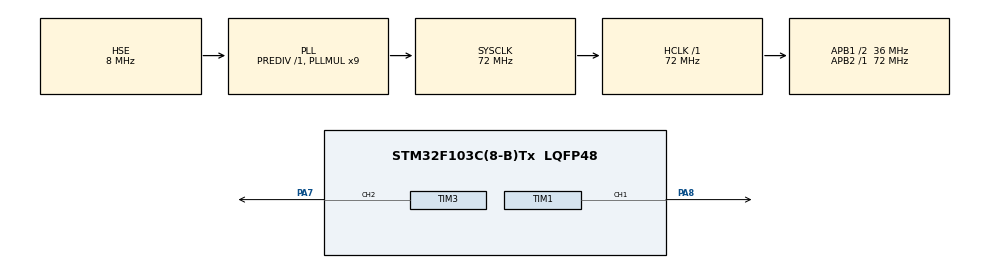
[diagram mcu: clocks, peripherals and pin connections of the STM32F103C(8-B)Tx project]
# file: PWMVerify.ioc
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Mcu.Family=STM32F1
Mcu.Name=STM32F103C(8-B)Tx
Mcu.Package=LQFP48
NVIC.PriorityGroup=NVIC_PRIORITYGROUP_4
PA13.Mode=Serial_Wire
PA13.Signal=SYS_JTMS-SWDIO
PA14.Mode=Serial_Wire
PA14.Signal=SYS_JTCK-SWCLK
PA7.Signal=S_TIM3_CH2
PA8.Signal=S_TIM1_CH1
PD0-OSC_IN.Mode=HSE-External-Oscillator
PD0-OSC_IN.Signal=RCC_OSC_IN
PD1-OSC_OUT.Mode=HSE-External-Oscillator
PD1-OSC_OUT.Signal=RCC_OSC_OUT
ProjectManager.HeapSize=0x200
ProjectManager.StackSize=0x400
ProjectManager.TargetToolchain=MDK-ARM V5.32
RCC.AHBFreq_Value=72000000
RCC.APB1CLKDivider=RCC_HCLK_DIV2
RCC.APB1Freq_Value=36000000
RCC.APB1TimFreq_Value=72000000
RCC.APB2Freq_Value=72000000
RCC.APB2TimFreq_Value=72000000
RCC.HCLKFreq_Value=72000000
RCC.PLLMUL=RCC_PLL_MUL9
RCC.PLLSourceVirtual=RCC_PLLSOURCE_HSE
RCC.SYSCLKFreq_VALUE=72000000
RCC.SYSCLKSource=RCC_SYSCLKSOURCE_PLLCLK
RCC.USBFreq_Value=72000000
SH.S_TIM1_CH1.0=TIM1_CH1,PWM Generation1 CH1
SH.S_TIM3_CH2.0=TIM3_CH2,PWM Generation2 CH2
TIM1.Channel-PWM\ Generation1\ CH1=TIM_CHANNEL_1
TIM3.Channel-PWM\ Generation2\ CH2=TIM_CHANNEL_2
VP_TIM1_VS_ClockSourceINT.Mode=Internal
VP_TIM3_VS_ClockSourceINT.Mode=Internal
board=custom

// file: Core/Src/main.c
/* USER CODE BEGIN Header */
/**
  ******************************************************************************
  * @file           : main.c
  * @brief          : Main program body
  ******************************************************************************
  * @attention
  *
  * Copyright (c) 2026 STMicroelectronics.
  * All rights reserved.
  *
  * This software is licensed under terms that can be found in the LICENSE file
  * in the root directory of this software component.
  * If no LICENSE file comes with this software, it is provided AS-IS.
  *
  ******************************************************************************
  */
/* USER CODE END Header */
#include "main.h"
#include "tim.h"
#include "gpio.h"

void SystemClock_Config(void);

int main(void)
{

  /* MCU Configuration--------------------------------------------------------*/

  /* Reset of all peripherals, Initializes the Flash interface and the Systick. */
  HAL_Init();

  /* Configure the system clock */
  SystemClock_Config();

  /* Initialize all configured peripherals */
  MX_GPIO_Init();
  MX_TIM1_Init();
  MX_TIM3_Init();
  /* USER CODE BEGIN 2 */
  /* ==========================================================================
   * 双定时器同频 PWM + 硬件主从触发死区（相移）
   *
   *   TIM1 (主) : PWM CH1 -> PA8   TRGO = Update Event
   *   TIM3 (从) : PWM CH2 -> PA7   Slave = Trigger Mode, TRGI = ITR0 (= TIM1 TRGO)
   *
   * 与 F4 参考工程 PWMGenerate 的实现保持一致:
   *   主从配置、CNT 预置、启动顺序全部集中在 MX_PWM_Start_PhaseLocked() 中,
   *   且放在 USER CODE 区, CubeMX 重新生成代码不会丢失。
   * ========================================================================== */

  /* 1) 设定两路 PWM 的占空比 */
  __HAL_TIM_SET_COMPARE(&htim1, TIM_CHANNEL_1, PWM_PULSE);    /* PA8: 高 [0, 1800)  */
  __HAL_TIM_SET_COMPARE(&htim3, TIM_CHANNEL_2, PWM_PULSE_T3); /* PA7: 高 [5, 1795)  */

  /* 2) 启动两路 PWM, 并一次性锁定 TIM1 / TIM3 的相位(死区) */
  MX_PWM_Start_PhaseLocked();

  /* USER CODE END 2 */

  /* Infinite loop */
  while (1)
  {

    /* USER CODE BEGIN 3 */
    /* ---- 调试用: 持续锁存寄存器, 在 Keil 的 Watch 窗口观察 -------------
     * g_dbg_tim3_cnt  : 若在不停变化 -> TIM3 计数器已被 TRGO 启动(正常)
     *                    若恒等于 3595   -> 没收到触发, 卡在预置值
     * g_dbg_tim3_sr   : bit6(TIF)=1 表示收到过 TRIGGER 事件
     * g_dbg_tim3_cr1  : bit0(CEN)=0 是触发模式的正常现象(由硬件 CNT_EN 启动)
     * g_dbg_tim1_cr2  : bit6:4(MMS) 应为 010 = TRGO 选更新事件
     * g_dbg_tim3_smcr : 应为 0x0006 (SMS=110 触发模式, TS=000 ITR0)
     * ------------------------------------------------------------------ */
    g_dbg_tim1_cr1  = TIM1->CR1;
    g_dbg_tim1_cr2  = TIM1->CR2;
    g_dbg_tim1_cnt  = TIM1->CNT;
    g_dbg_tim3_cr1  = TIM3->CR1;
    g_dbg_tim3_smcr = TIM3->SMCR;
    g_dbg_tim3_cnt  = TIM3->CNT;
    g_dbg_tim3_sr   = TIM3->SR;
  }
  /* USER CODE END 3 */
}

void SystemClock_Config(void)
{
  RCC_OscInitTypeDef RCC_OscInitStruct = {0};
  RCC_ClkInitTypeDef RCC_ClkInitStruct = {0};

  /** Initializes the RCC Oscillators according to the specified parameters
  * in the RCC_OscInitTypeDef structure.
  */
  RCC_OscInitStruct.OscillatorType = RCC_OSCILLATORTYPE_HSE;
  RCC_OscInitStruct.HSEState = RCC_HSE_ON;
  RCC_OscInitStruct.HSEPredivValue = RCC_HSE_PREDIV_DIV1;
  RCC_OscInitStruct.HSIState = RCC_HSI_ON;
  RCC_OscInitStruct.PLL.PLLState = RCC_PLL_ON;
  RCC_OscInitStruct.PLL.PLLSource = RCC_PLLSOURCE_HSE;
  RCC_OscInitStruct.PLL.PLLMUL = RCC_PLL_MUL9;
  if (HAL_RCC_OscConfig(&RCC_OscInitStruct) != HAL_OK)
  {
    Error_Handler();
  }

  /** Initializes the CPU, AHB and APB buses clocks
  */
  RCC_ClkInitStruct.ClockType = RCC_CLOCKTYPE_HCLK|RCC_CLOCKTYPE_SYSCLK
                              |RCC_CLOCKTYPE_PCLK1|RCC_CLOCKTYPE_PCLK2;
  RCC_ClkInitStruct.SYSCLKSource = RCC_SYSCLKSOURCE_PLLCLK;
  RCC_ClkInitStruct.AHBCLKDivider = RCC_SYSCLK_DIV1;
  RCC_ClkInitStruct.APB1CLKDivider = RCC_HCLK_DIV2;
  RCC_ClkInitStruct.APB2CLKDivider = RCC_HCLK_DIV1;

  if (HAL_RCC_ClockConfig(&RCC_ClkInitStruct, FLASH_LATENCY_2) != HAL_OK)
  {
    Error_Handler();
  }
}

void Error_Handler(void)
{
  __disable_irq();
  while (1)
  {
  }
}
